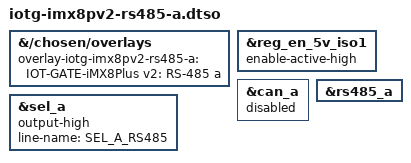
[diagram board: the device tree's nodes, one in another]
#include "overlay.h"

&{/chosen/overlays} {
	overlay-iotg-imx8pv2-rs485-a = "IOT-GATE-iMX8Plus v2: RS-485 a";
};

/* Enable ISO1_5V */
&reg_en_5v_iso1 {
	enable-active-high;
};

/* Disable CAN A interface */
&can_a {
	status = "disabled";
};

/* Enable RS485 A interface */
&rs485_a {
	status = "okay";
};

/* Select RS485 signals on the MUX-A */
&sel_a {
	output-high;
	line-name = "SEL_A_RS485";
	status = "okay";
};
